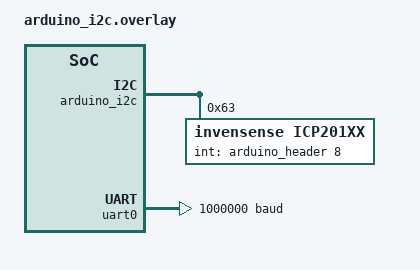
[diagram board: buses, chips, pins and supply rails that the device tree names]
/*
 * Copyright (c) 2024, TDK Invensense
 *
 * SPDX-License-Identifier: Apache-2.0
 */

/*
 * Example configuration of a icp201xx device on an Arduino I2C bus.
 *
 * Device address 0x63 is assumed. Your device may have a different
 * address; check your device documentation if unsure.
 */
&arduino_i2c {
	status = "okay";
	icp201xx@63 {
		compatible = "invensense,icp201xx";
		reg = <0x63>;
		int-gpios = <&arduino_header 8 GPIO_ACTIVE_HIGH>; /* D2 */
	};
};

/*
 * Increase native UART speed to report sensor data.
 */
&uart0 {
	compatible = "nordic,nrf-uarte";
	status = "okay";
	current-speed = <1000000>;
};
